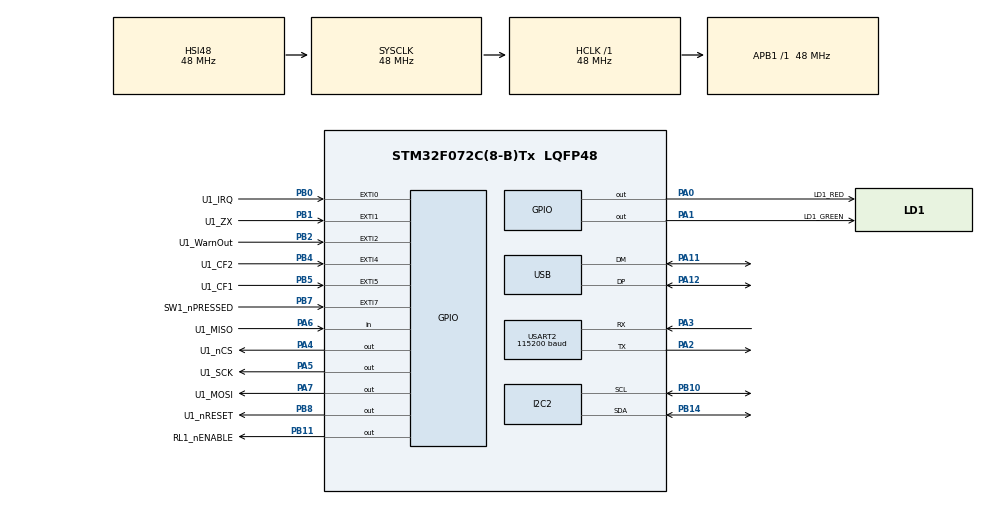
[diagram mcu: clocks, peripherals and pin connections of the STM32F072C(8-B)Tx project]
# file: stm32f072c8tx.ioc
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Mcu.Family=STM32F0
Mcu.Name=STM32F072C(8-B)Tx
Mcu.Package=LQFP48
NVIC.EXTI0_1_IRQn=true\:2\:0\:true\:false\:true\:true\:true
NVIC.EXTI2_3_IRQn=true\:2\:0\:true\:false\:true\:true\:true
NVIC.EXTI4_15_IRQn=true\:2\:0\:true\:false\:true\:true\:true
NVIC.TIM2_IRQn=true\:3\:0\:true\:false\:true\:true\:true
NVIC.USB_IRQn=true\:0\:0\:false\:false\:true\:false\:true
PA0.GPIO_Label=LD1_RED
PA0.Signal=GPIO_Output
PA1.GPIO_Label=LD1_GREEN
PA1.Signal=GPIO_Output
PA11.Mode=Device
PA11.Signal=USB_DM
PA12.Mode=Device
PA12.Signal=USB_DP
PA13.Mode=Serial_Wire
PA13.Signal=SYS_SWDIO
PA14.Mode=Serial_Wire
PA14.Signal=SYS_SWCLK
PA2.Mode=Asynchronous
PA2.Signal=USART2_TX
PA3.Mode=Asynchronous
PA3.Signal=USART2_RX
PA4.GPIO_Label=U1_nCS
PA4.PinState=GPIO_PIN_SET
PA4.Signal=GPIO_Output
PA5.GPIO_Label=U1_SCK
PA5.PinState=GPIO_PIN_SET
PA5.Signal=GPIO_Output
PA6.GPIO_Label=U1_MISO
PA6.Signal=GPIO_Input
PA7.GPIO_Label=U1_MOSI
PA7.Signal=GPIO_Output
PB0.GPIO_Label=U1_IRQ
PB0.GPIO_ModeDefaultEXTI=GPIO_MODE_IT_FALLING
PB0.Signal=GPXTI0
PB1.GPIO_Label=U1_ZX
PB1.GPIO_ModeDefaultEXTI=GPIO_MODE_IT_FALLING
PB1.Signal=GPXTI1
PB10.Mode=I2C
PB10.Signal=I2C2_SCL
PB11.GPIO_Label=RL1_nENABLE
PB11.Signal=GPIO_Output
PB14.Mode=I2C
PB14.Signal=I2C2_SDA
PB2.GPIO_Label=U1_WarnOut
PB2.GPIO_ModeDefaultEXTI=GPIO_MODE_IT_FALLING
PB2.Signal=GPXTI2
PB4.GPIO_Label=U1_CF2
PB4.Signal=GPXTI4
PB5.GPIO_Label=U1_CF1
PB5.Signal=GPXTI5
PB7.GPIO_Label=SW1_nPRESSED
PB7.GPIO_ModeDefaultEXTI=GPIO_MODE_IT_FALLING
PB7.GPIO_PuPd=GPIO_PULLUP
PB7.Signal=GPXTI7
PB8.GPIO_Label=U1_nRESET
PB8.PinState=GPIO_PIN_SET
PB8.Signal=GPIO_Output
PC14-OSC32_IN.Mode=LSE-External-Oscillator
PC14-OSC32_IN.Signal=RCC_OSC32_IN
PC15-OSC32_OUT.Mode=LSE-External-Oscillator
PC15-OSC32_OUT.Signal=RCC_OSC32_OUT
PF0-OSC_IN.Mode=HSE-External-Oscillator
PF0-OSC_IN.Signal=RCC_OSC_IN
PF1-OSC_OUT.Mode=HSE-External-Oscillator
PF1-OSC_OUT.Signal=RCC_OSC_OUT
ProjectManager.HeapSize=0x200
ProjectManager.StackSize=0x400
ProjectManager.TargetToolchain=Makefile
RCC.AHBFreq_Value=48000000
RCC.APB1Freq_Value=48000000
RCC.APB1TimFreq_Value=48000000
RCC.HCLKFreq_Value=48000000
RCC.SYSCLKFreq_VALUE=48000000
RCC.SYSCLKSource=RCC_SYSCLKSOURCE_HSI48
TIM2.AutoReloadPreload=TIM_AUTORELOAD_PRELOAD_ENABLE
TIM2.ClockDivision=TIM_CLOCKDIVISION_DIV4
TIM2.Period=2400
USART2.BaudRate=115200
USART2.VirtualMode-Asynchronous=VM_ASYNC
USB_DEVICE.CLASS_NAME_FS=CDC
USB_DEVICE.MANUFACTURER_STRING=Belmoor Ldt.
USB_DEVICE.PRODUCT_STRING_CDC_FS=PM 10A Ver\:05
USB_DEVICE.VirtualMode=Cdc
USB_DEVICE.VirtualModeFS=Cdc_FS
VP_TIM2_VS_ClockSourceINT.Mode=Internal
VP_USB_DEVICE_VS_USB_DEVICE_CDC_FS.Mode=CDC_FS
board=custom

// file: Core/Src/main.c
/* USER CODE BEGIN Header */
/**
  ******************************************************************************
  * @file           : main.c
  * @brief          : Main program body
  ******************************************************************************
  * @attention
  *
  * <h2><center>&copy; Copyright (c) 2021 STMicroelectronics.
  * All rights reserved.</center></h2>
  *
  * This software component is licensed by ST under Ultimate Liberty license
  * SLA0044, the "License"; You may not use this file except in compliance with
  * the License. You may obtain a copy of the License at:
  *                             www.st.com/SLA0044
  *
  ******************************************************************************
  */
/* USER CODE END Header */
#include "main.h"
#include "i2c.h"
#include "tim.h"
#include "usart.h"
#include "usb_device.h"
#include "gpio.h"

void SystemClock_Config(void);
/* USER CODE BEGIN PFP */
void mainloop(void);
/* USER CODE END PFP */

int main(void)
{

  /* MCU Configuration--------------------------------------------------------*/

  /* Reset of all peripherals, Initializes the Flash interface and the Systick. */
  HAL_Init();

  /* Configure the system clock */
  SystemClock_Config();

  /* Initialize all configured peripherals */
  MX_GPIO_Init();
  MX_I2C2_Init();
  MX_USART2_UART_Init();
  MX_USB_DEVICE_Init();
  MX_TIM2_Init();
  /* USER CODE BEGIN 2 */
  HAL_TIM_Base_Start_IT(&htim2);
  /* USER CODE END 2 */

  /* Infinite loop */
  /* USER CODE BEGIN WHILE */
  while (1)
  {
    mainloop();
    /* USER CODE END WHILE */

  }
}

void SystemClock_Config(void)
{
  RCC_OscInitTypeDef RCC_OscInitStruct = {0};
  RCC_ClkInitTypeDef RCC_ClkInitStruct = {0};
  RCC_PeriphCLKInitTypeDef PeriphClkInit = {0};

  /** Initializes the RCC Oscillators according to the specified parameters
  * in the RCC_OscInitTypeDef structure.
  */
  RCC_OscInitStruct.OscillatorType = RCC_OSCILLATORTYPE_HSI48;
  RCC_OscInitStruct.HSI48State = RCC_HSI48_ON;
  RCC_OscInitStruct.PLL.PLLState = RCC_PLL_NONE;
  if (HAL_RCC_OscConfig(&RCC_OscInitStruct) != HAL_OK)
  {
    Error_Handler();
  }
  /** Initializes the CPU, AHB and APB buses clocks
  */
  RCC_ClkInitStruct.ClockType = RCC_CLOCKTYPE_HCLK|RCC_CLOCKTYPE_SYSCLK
                              |RCC_CLOCKTYPE_PCLK1;
  RCC_ClkInitStruct.SYSCLKSource = RCC_SYSCLKSOURCE_HSI48;
  RCC_ClkInitStruct.AHBCLKDivider = RCC_SYSCLK_DIV1;
  RCC_ClkInitStruct.APB1CLKDivider = RCC_HCLK_DIV1;

  if (HAL_RCC_ClockConfig(&RCC_ClkInitStruct, FLASH_LATENCY_1) != HAL_OK)
  {
    Error_Handler();
  }
  PeriphClkInit.PeriphClockSelection = RCC_PERIPHCLK_USB|RCC_PERIPHCLK_USART2;
  PeriphClkInit.Usart2ClockSelection = RCC_USART2CLKSOURCE_PCLK1;
  PeriphClkInit.UsbClockSelection = RCC_USBCLKSOURCE_HSI48;

  if (HAL_RCCEx_PeriphCLKConfig(&PeriphClkInit) != HAL_OK)
  {
    Error_Handler();
  }
}

void Error_Handler(void)
{
  __disable_irq();
  while (1)
  {
  }
}

/************************ (C) COPYRIGHT STMicroelectronics *****END OF FILE****/
